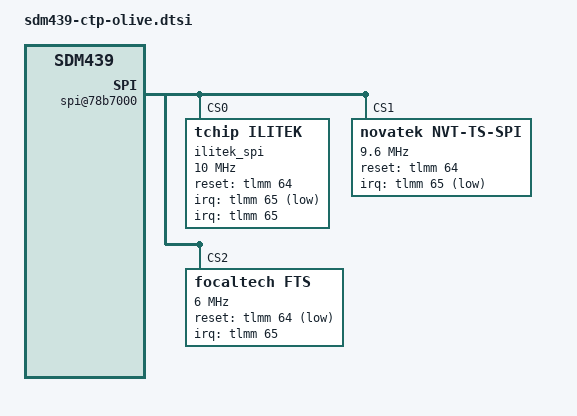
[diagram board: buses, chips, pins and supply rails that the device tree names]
/* Copyright (c) 2018, The Linux Foundation. All rights reserved.
 * Copyright (C) 2021 XiaoMi, Inc.
 *
 * it under the terms of the GNU General Public License version 2 and
 * only version 2 as published by the Free Software Foundation.
 *
 * This program is distributed in the hope that it will be useful,
 * but WITHOUT ANY WARRANTY; without even the implied warranty of
 * MERCHANTABILITY or FITNESS FOR A PARTICULAR PURPOSE.  See the
 * GNU General Public License for more details.
 */

/*
 * As a general rule, only version-specific property overrides should be placed
 * inside this file. However, device definitions should be placed inside the
 * yep_product_ql1001_flatform.dtsi file.
 */

&tlmm {
		ts_int_default: ts_int_default {
			mux {
				pins = "gpio65";
				function = "gpio";
			};
			config {
				pins = "gpio65";
				drive-strength = <8>;
				/*bias-pull-up;*/
				input-enable;
				bias-disable;
			};
		};

		ts_int_output_high: ts_int_output_high {
			mux {
				pins = "gpio65";
				function = "gpio";
			};
			config {
				pins = "gpio65";
				drive-strength = <8>;
				output-high;
				bias-pull-up;
			};
		};

		ts_int_output_low: ts_int_output_low {
			mux {
				pins = "gpio65";
				function = "gpio";
			};
			config {
				pins = "gpio65";
				drive-strength = <8>;
				bias-pull-down;
				output-low;
			};
		};

		ts_int_input: ts_int_input {
			mux {
				pins = "gpio65";
				function = "gpio";
			};
			config {
				pins = "gpio65";
				drive-strength = <8>;
				input-enable;
				bias-disable;
			};
		};

		pmx_ts_reset_release {
			ts_as_reset: ts_as_reset {
				mux {
					pins = "gpio64";
					function = "gpio";
				};

				config {
					pins = "gpio64";
					drive-strength = <8>;
					input-enable;
					bias-disable;
				};
			};
		};

		pmx_ts_reset_suspend {
			ts_reset_suspend: ts_reset_suspend {
				mux {
					pins = "gpio64";
					function = "gpio";
				};

				config {
					pins = "gpio64";
					drive-strength = <8>;
					bias-pull-down;
					output-low;
				};
			};
		};

		pmx_ts_reset_active {
			ts_reset_active: ts_reset_active {
				mux {
					pins = "gpio64";
					function = "gpio";
				};

				config {
					pins = "gpio64";
					drive-strength = <8>;
					bias-pull-up;
					output-high;
				};
			};
		};

		pmx_ts_rst_active {
				ts_rst_active: ts_rst_active {
						mux {
								pins = "gpio64";
								function = "gpio";
						};

						config {
								pins = "gpio64";
								drive-strength = <16>;
								bias-pull-up;
						};
				};
		};

		pmx_ts_rst_suspend {
			ts_rst_suspend: ts_rst_suspend {
						mux {
								pins = "gpio64";
								function = "gpio";
						};

						config {
								pins = "gpio64";
								drive-strength = <2>;
								bias-pull-down;
						};
				};
		};
};


&soc {
	spi@78b7000 {
		status = "okay";
		ilitek_spi@00 {
		    compatible = "tchip,ilitek";
			reg = <0>;
			chip-name = "ILITEK_TDDI";
			status = "ok";

		    poll_mode = <0>;
			spi-max-frequency = <10000000>;
			touch,reset-gpio = <&tlmm 64 0x00>;
			touch,irq-gpio = <&tlmm 65 0x2001>;
			interrupt-parent = <&tlmm>;
			interrupts = <65 0x0>;

			touchpanel,max-num-support = <10>;
			touchpanel,tx-rx-num = <18 32>;
			touchpanel,panel-coords = <720 1520>;
			touchpanel,display-coords = <720 1520>;

			pinctrl-names = "active", "suspend";
			pinctrl-0 = <&ts_int_active &ts_reset_active>;
			pinctrl-1 = <&ts_int_suspend &ts_reset_suspend>;

			incell_screen;
			edge_limit_support;
			black_gesture_support;
			charger_pump_support;
			esd_handle_support;
			//spurious_fingerprint_support;
			//lcd_trigger_fp_check;
			black_gesture_test_support;
			noflash_support;
			smart_gesture_support;

			spi-cpol; //CPOL bit set for SPI polarity
			spi-cpha; //CPHA bit set for SPI Phase
			spi-cs-high; //CS Active High

			/*
			*Virtual Key Config:
			*1:touchpanel,button-type: <virtualkey_type  supportted_button-map>
			*virtualkey_type:
			*Type 1: using board_properties
			*Type 2: using same IC (button zone&& touch zone are seprate)
			*Type 3: using diffrent IC (button zone&& touch zone are seprate)
			*Type 4: No need of virtual key process
			*supportted_button-map:select|menu|home|back
			*
			*2:touchpanel,button-map
			*type (X1,Y1)(X2,Y2)(X3,Y3)(Width_X,Hight_Y)--Only when button-type is 0
			*/

			touchpanel,button-type = <4>;
		};
		novatek@1 {
		compatible = "novatek,NVT-ts-spi";
		reg = <1>; //Same as CS ID
		status = "ok";

		spi-max-frequency = <9600000>;	//4800000,9600000,15000000,19200000
		novatek,reset-gpio = <&tlmm 64 0x00>;
		novatek,irq-gpio = <&tlmm 65 0x2001>;

		/* 525 */
		//novatek,swrst-n8-addr = <0x01F01A>;

		/* 672A, 525B, 675 */
		novatek,swrst-n8-addr = <0x03F0FE>;
		novatek,spi-rd-fast-addr = <0x03F310>;

		/* MP */
		novatek,mp-support-dt;

		/* for Xiaomi C3I 525B BOE 6.217" */
		novatek-mp-criteria-591C@0 {
			#address-cells = <1>;
			#size-cells = <0>;
			compatible = "novatek-mp-criteria-591C";

			/* MP Config */
			ic_x_cfg_size = <18>;
			ic_y_cfg_size = <32>;
			ic_key_cfg_size = <4>;
			x_channel = <18>;
			y_channel = <32>;
			ain_x = <0 1 2 3 4 5 6 7 8 9 10 11 12 13 14 15 16 17>;
			ain_y = <0 1 2 3 4 5 6 7 8 9 10 11 12 13 14 15 16 17
				18 19 20 21 22 23 24 25 26 27 28 29 30 31>;
			ain_key = <0 1 2 0xFF>;
			/* MP Criteria */
			//PS_Config_Lmt_Short_Rawdata_P = <
			    ps_config_lmt_short_rawdata_p = <
				14008 14008 14008 14008 14008 14008 14008 14008 14008 14008 14008 14008 14008 14008 14008 14008 14008 14008
				14008 14008 14008 14008 14008 14008 14008 14008 14008 14008 14008 14008 14008 14008 14008 14008 14008 14008
				14008 14008 14008 14008 14008 14008 14008 14008 14008 14008 14008 14008 14008 14008 14008 14008 14008 14008
				14008 14008 14008 14008 14008 14008 14008 14008 14008 14008 14008 14008 14008 14008 14008 14008 14008 14008
				14008 14008 14008 14008 14008 14008 14008 14008 14008 14008 14008 14008 14008 14008 14008 14008 14008 14008
				14008 14008 14008 14008 14008 14008 14008 14008 14008 14008 14008 14008 14008 14008 14008 14008 14008 14008
				14008 14008 14008 14008 14008 14008 14008 14008 14008 14008 14008 14008 14008 14008 14008 14008 14008 14008
				14008 14008 14008 14008 14008 14008 14008 14008 14008 14008 14008 14008 14008 14008 14008 14008 14008 14008
				14008 14008 14008 14008 14008 14008 14008 14008 14008 14008 14008 14008 14008 14008 14008 14008 14008 14008
				14008 14008 14008 14008 14008 14008 14008 14008 14008 14008 14008 14008 14008 14008 14008 14008 14008 14008
				14008 14008 14008 14008 14008 14008 14008 14008 14008 14008 14008 14008 14008 14008 14008 14008 14008 14008
				14008 14008 14008 14008 14008 14008 14008 14008 14008 14008 14008 14008 14008 14008 14008 14008 14008 14008
				14008 14008 14008 14008 14008 14008 14008 14008 14008 14008 14008 14008 14008 14008 14008 14008 14008 14008
				14008 14008 14008 14008 14008 14008 14008 14008 14008 14008 14008 14008 14008 14008 14008 14008 14008 14008
				14008 14008 14008 14008 14008 14008 14008 14008 14008 14008 14008 14008 14008 14008 14008 14008 14008 14008
				14008 14008 14008 14008 14008 14008 14008 14008 14008 14008 14008 14008 14008 14008 14008 14008 14008 14008
				14008 14008 14008 14008 14008 14008 14008 14008 14008 14008 14008 14008 14008 14008 14008 14008 14008 14008
				14008 14008 14008 14008 14008 14008 14008 14008 14008 14008 14008 14008 14008 14008 14008 14008 14008 14008
				14008 14008 14008 14008 14008 14008 14008 14008 14008 14008 14008 14008 14008 14008 14008 14008 14008 14008
				14008 14008 14008 14008 14008 14008 14008 14008 14008 14008 14008 14008 14008 14008 14008 14008 14008 14008
				14008 14008 14008 14008 14008 14008 14008 14008 14008 14008 14008 14008 14008 14008 14008 14008 14008 14008
				14008 14008 14008 14008 14008 14008 14008 14008 14008 14008 14008 14008 14008 14008 14008 14008 14008 14008
				14008 14008 14008 14008 14008 14008 14008 14008 14008 14008 14008 14008 14008 14008 14008 14008 14008 14008
				14008 14008 14008 14008 14008 14008 14008 14008 14008 14008 14008 14008 14008 14008 14008 14008 14008 14008
				14008 14008 14008 14008 14008 14008 14008 14008 14008 14008 14008 14008 14008 14008 14008 14008 14008 14008
				14008 14008 14008 14008 14008 14008 14008 14008 14008 14008 14008 14008 14008 14008 14008 14008 14008 14008
				14008 14008 14008 14008 14008 14008 14008 14008 14008 14008 14008 14008 14008 14008 14008 14008 14008 14008
				14008 14008 14008 14008 14008 14008 14008 14008 14008 14008 14008 14008 14008 14008 14008 14008 14008 14008
				14008 14008 14008 14008 14008 14008 14008 14008 14008 14008 14008 14008 14008 14008 14008 14008 14008 14008
				14008 14008 14008 14008 14008 14008 14008 14008 14008 14008 14008 14008 14008 14008 14008 14008 14008 14008
				14008 14008 14008 14008 14008 14008 14008 14008 14008 14008 14008 14008 14008 14008 14008 14008 14008 14008
				14008 14008 14008 14008 14008 14008 14008 14008 14008 14008 14008 14008 14008 14008 14008 14008 14008 14008
				14008 14008 14008>;

			//PS_Config_Lmt_Short_Rawdata_N = <
			    ps_config_lmt_short_rawdata_n = <
				11376 11376 11376 11376 11376 11376 11376 11376 11376 11376 11376 11376 11376 11376 11376 11376 11376 11376
				11376 11376 11376 11376 11376 11376 11376 11376 11376 11376 11376 11376 11376 11376 11376 11376 11376 11376
				11376 11376 11376 11376 11376 11376 11376 11376 11376 11376 11376 11376 11376 11376 11376 11376 11376 11376
				11376 11376 11376 11376 11376 11376 11376 11376 11376 11376 11376 11376 11376 11376 11376 11376 11376 11376
				11376 11376 11376 11376 11376 11376 11376 11376 11376 11376 11376 11376 11376 11376 11376 11376 11376 11376
				11376 11376 11376 11376 11376 11376 11376 11376 11376 11376 11376 11376 11376 11376 11376 11376 11376 11376
				11376 11376 11376 11376 11376 11376 11376 11376 11376 11376 11376 11376 11376 11376 11376 11376 11376 11376
				11376 11376 11376 11376 11376 11376 11376 11376 11376 11376 11376 11376 11376 11376 11376 11376 11376 11376
				11376 11376 11376 11376 11376 11376 11376 11376 11376 11376 11376 11376 11376 11376 11376 11376 11376 11376
				11376 11376 11376 11376 11376 11376 11376 11376 11376 11376 11376 11376 11376 11376 11376 11376 11376 11376
				11376 11376 11376 11376 11376 11376 11376 11376 11376 11376 11376 11376 11376 11376 11376 11376 11376 11376
				11376 11376 11376 11376 11376 11376 11376 11376 11376 11376 11376 11376 11376 11376 11376 11376 11376 11376
				11376 11376 11376 11376 11376 11376 11376 11376 11376 11376 11376 11376 11376 11376 11376 11376 11376 11376
				11376 11376 11376 11376 11376 11376 11376 11376 11376 11376 11376 11376 11376 11376 11376 11376 11376 11376
				11376 11376 11376 11376 11376 11376 11376 11376 11376 11376 11376 11376 11376 11376 11376 11376 11376 11376
				11376 11376 11376 11376 11376 11376 11376 11376 11376 11376 11376 11376 11376 11376 11376 11376 11376 11376
				11376 11376 11376 11376 11376 11376 11376 11376 11376 11376 11376 11376 11376 11376 11376 11376 11376 11376
				11376 11376 11376 11376 11376 11376 11376 11376 11376 11376 11376 11376 11376 11376 11376 11376 11376 11376
				11376 11376 11376 11376 11376 11376 11376 11376 11376 11376 11376 11376 11376 11376 11376 11376 11376 11376
				11376 11376 11376 11376 11376 11376 11376 11376 11376 11376 11376 11376 11376 11376 11376 11376 11376 11376
				11376 11376 11376 11376 11376 11376 11376 11376 11376 11376 11376 11376 11376 11376 11376 11376 11376 11376
				11376 11376 11376 11376 11376 11376 11376 11376 11376 11376 11376 11376 11376 11376 11376 11376 11376 11376
				11376 11376 11376 11376 11376 11376 11376 11376 11376 11376 11376 11376 11376 11376 11376 11376 11376 11376
				11376 11376 11376 11376 11376 11376 11376 11376 11376 11376 11376 11376 11376 11376 11376 11376 11376 11376
				11376 11376 11376 11376 11376 11376 11376 11376 11376 11376 11376 11376 11376 11376 11376 11376 11376 11376
				11376 11376 11376 11376 11376 11376 11376 11376 11376 11376 11376 11376 11376 11376 11376 11376 11376 11376
				11376 11376 11376 11376 11376 11376 11376 11376 11376 11376 11376 11376 11376 11376 11376 11376 11376 11376
				11376 11376 11376 11376 11376 11376 11376 11376 11376 11376 11376 11376 11376 11376 11376 11376 11376 11376
				11376 11376 11376 11376 11376 11376 11376 11376 11376 11376 11376 11376 11376 11376 11376 11376 11376 11376
				11376 11376 11376 11376 11376 11376 11376 11376 11376 11376 11376 11376 11376 11376 11376 11376 11376 11376
				11376 11376 11376 11376 11376 11376 11376 11376 11376 11376 11376 11376 11376 11376 11376 11376 11376 11376
				11376 11376 11376 11376 11376 11376 11376 11376 11376 11376 11376 11376 11376 11376 11376 11376 11376 11376
				10000 10000 10000>;

			//PS_Config_Lmt_Open_Rawdata_P = <
			    ps_config_lmt_open_rawdata_p = <
				65535 2420 2548 2510 2524 2457 2476 2326 65535 65535 2352 2500 2506 2542 2507 2476 2371 65535
				2262 2298 2356 2332 2357 2328 2349 2319 2251 2276 2354 2373 2373 2382 2339 2303 2259 2205
				2303 2314 2375 2354 2381 2352 2367 2339 2346 2382 2381 2398 2399 2410 2364 2324 2280 2248
				2321 2333 2396 2375 2402 2374 2389 2357 2364 2410 2410 2433 2434 2444 2398 2360 2315 2286
				2322 2332 2391 2373 2394 2367 2381 2352 2360 2380 2380 2401 2399 2413 2375 2340 2298 2272
				2340 2354 2409 2394 2413 2388 2394 2367 2375 2408 2406 2427 2431 2447 2409 2373 2333 2305
				2370 2387 2454 2437 2459 2433 2440 2415 2424 2441 2438 2457 2459 2478 2438 2405 2353 2324
				2388 2408 2475 2464 2476 2454 2459 2437 2445 2462 2461 2479 2483 2500 2471 2437 2385 2356
				2374 2388 2454 2438 2454 2429 2437 2415 2420 2431 2430 2451 2451 2471 2441 2416 2367 2340
				2405 2420 2482 2471 2482 2458 2464 2441 2447 2451 2451 2472 2478 2494 2471 2447 2398 2371
				2434 2450 2517 2503 2521 2494 2500 2476 2480 2497 2497 2521 2524 2543 2518 2494 2444 2416
				2450 2465 2528 2518 2534 2508 2513 2490 2493 2518 2520 2542 2545 2564 2542 2518 2471 2443
				2441 2454 2514 2497 2517 2492 2496 2469 2476 2478 2480 2506 2507 2528 2508 2492 2450 2424
				2464 2475 2534 2520 2536 2510 2517 2489 2493 2503 2506 2531 2534 2555 2543 2527 2486 2459
				2517 2529 2590 2577 2595 2569 2576 2548 2552 2532 2536 2562 2563 2584 2574 2559 2515 2487
				2521 2531 2590 2580 2594 2567 2574 2548 2549 2552 2556 2581 2585 2605 2599 2585 2542 2514
				2515 2527 2573 2577 2594 2569 2577 2550 2549 2521 2524 2546 2550 2570 2571 2573 2538 2515
				2524 2534 2578 2578 2597 2573 2580 2553 2553 2548 2553 2576 2580 2598 2599 2608 2574 2552
				2576 2591 2634 2636 2657 2633 2640 2612 2613 2577 2580 2604 2608 2626 2626 2637 2606 2581
				2580 2591 2632 2629 2653 2627 2636 2608 2609 2598 2602 2625 2629 2647 2648 2661 2633 2609
				2577 2587 2619 2618 2640 2613 2632 2605 2609 2560 2562 2583 2576 2598 2598 2615 2591 2571
				2573 2581 2623 2615 2633 2606 2625 2597 2601 2591 2592 2616 2609 2629 2634 2657 2630 2609
				2639 2646 2689 2682 2702 2675 2692 2667 2669 2625 2627 2651 2643 2664 2668 2692 2664 2644
				2637 2646 2688 2678 2700 2672 2689 2662 2667 2647 2650 2674 2667 2688 2690 2720 2693 2674
				2626 2633 2669 2657 2682 2650 2665 2639 2643 2594 2595 2618 2611 2639 2636 2665 2644 2629
				2616 2622 2658 2644 2669 2637 2654 2625 2632 2612 2611 2637 2630 2660 2657 2685 2667 2654
				2685 2689 2725 2718 2746 2713 2724 2696 2702 2653 2650 2679 2674 2706 2697 2725 2704 2690
				2668 2671 2704 2696 2724 2696 2707 2674 2679 2671 2664 2702 2695 2723 2716 2744 2725 2710
				2644 2651 2679 2669 2692 2667 2676 2643 2650 2604 2592 2633 2623 2655 2646 2676 2658 2648
				2277 2658 2688 2674 2696 2671 2683 2650 2657 2640 2627 2669 2658 2692 2682 2716 2697 2293
				2328 2716 2744 2731 2753 2730 2742 2709 2717 2669 2655 2697 2685 2720 2710 2746 2727 2321
				2308 2620 2738 2724 2749 2727 2739 2707 2721 2713 2690 2734 2720 2756 2746 2784 2675 2346
				4096 4096 4096>;

			//PS_Config_Lmt_Open_Rawdata_N = <
			    ps_config_lmt_open_rawdata_n = <
				(-65535) 1037 1092 1075 1081 1053 1061 997 (-65535) (-65535) 1008 1071 1074 1089 1074 1061 1016 (-65535)
				969 985 1009 999 1010 997 1006 994 964 975 1009 1017 1017 1021 1002 987 968 945
				987 991 1018 1009 1020 1008 1014 1002 1005 1021 1020 1027 1028 1033 1013 996 977 963
				994 1000 1027 1018 1029 1017 1024 1010 1013 1033 1033 1042 1043 1047 1027 1011 992 979
				995 999 1024 1017 1026 1014 1020 1008 1011 1020 1020 1029 1028 1034 1018 1003 985 973
				1003 1009 1032 1026 1034 1023 1026 1014 1018 1032 1031 1040 1042 1048 1032 1017 1000 988
				1015 1023 1051 1044 1054 1042 1045 1035 1039 1046 1045 1053 1054 1062 1045 1030 1008 996
				1023 1032 1060 1056 1061 1051 1054 1044 1048 1055 1054 1062 1064 1071 1059 1044 1022 1009
				1017 1023 1051 1045 1051 1041 1044 1035 1037 1042 1041 1050 1050 1059 1046 1035 1014 1003
				1030 1037 1063 1059 1063 1053 1056 1046 1048 1050 1050 1059 1062 1069 1059 1048 1027 1016
				1043 1050 1078 1072 1080 1069 1071 1061 1063 1070 1070 1080 1081 1090 1079 1069 1047 1035
				1050 1056 1083 1079 1086 1075 1077 1067 1068 1079 1080 1089 1090 1099 1089 1079 1059 1047
				1046 1051 1077 1070 1078 1068 1069 1058 1061 1062 1063 1074 1074 1083 1075 1068 1050 1039
				1056 1060 1086 1080 1087 1075 1078 1066 1068 1072 1074 1084 1086 1095 1090 1083 1065 1054
				1078 1084 1110 1104 1112 1101 1104 1092 1093 1085 1087 1098 1098 1107 1103 1096 1078 1066
				1080 1084 1110 1105 1111 1100 1103 1092 1092 1093 1095 1106 1108 1116 1114 1108 1089 1077
				1078 1083 1102 1104 1111 1101 1104 1093 1092 1080 1081 1091 1093 1101 1102 1102 1087 1078
				1081 1086 1105 1105 1113 1102 1105 1094 1094 1092 1094 1104 1105 1113 1114 1117 1103 1093
				1104 1110 1129 1129 1138 1128 1131 1119 1120 1104 1105 1116 1117 1125 1125 1130 1117 1106
				1105 1110 1128 1126 1137 1126 1129 1117 1118 1113 1115 1125 1126 1134 1135 1140 1128 1118
				1104 1108 1122 1122 1131 1120 1128 1116 1118 1097 1098 1107 1104 1113 1113 1120 1110 1102
				1102 1106 1124 1120 1128 1117 1125 1113 1114 1110 1111 1121 1118 1126 1129 1138 1127 1118
				1131 1134 1152 1149 1158 1146 1153 1143 1144 1125 1126 1136 1132 1141 1143 1153 1141 1133
				1130 1134 1152 1147 1157 1145 1152 1141 1143 1134 1135 1146 1143 1152 1153 1165 1154 1146
				1125 1128 1144 1138 1149 1135 1142 1131 1132 1111 1112 1122 1119 1131 1129 1142 1133 1126
				1121 1123 1139 1133 1144 1130 1137 1125 1128 1119 1119 1130 1127 1140 1138 1150 1143 1137
				1150 1152 1168 1165 1177 1162 1167 1155 1158 1137 1135 1148 1146 1159 1156 1168 1159 1153
				1143 1144 1159 1155 1167 1155 1160 1146 1148 1144 1141 1158 1155 1167 1164 1176 1168 1161
				1133 1136 1148 1144 1153 1143 1147 1132 1135 1116 1111 1128 1124 1138 1134 1147 1139 1135
				976 1139 1152 1146 1155 1144 1150 1135 1138 1131 1126 1144 1139 1153 1149 1164 1156 982
				997 1164 1176 1170 1180 1170 1175 1161 1164 1144 1138 1156 1150 1165 1161 1177 1168 994
				989 1123 1173 1167 1178 1168 1174 1160 1166 1162 1153 1171 1165 1181 1177 1193 1146 1005
				50 50 50>;

			//PS_Config_Lmt_FW_Rawdata_P = <
			   ps_config_lmt_fw_rawdata_p = <
				65535 837 841 840 840 833 838 840 65535 65535 833 841 828 837 849 851 851 65535
				838 835 847 842 834 845 828 831 842 833 833 838 847 833 834 847 840 835
				837 848 851 851 848 848 838 840 824 844 844 847 849 838 830 845 845 833
				844 840 837 841 841 848 841 845 842 851 845 842 834 834 842 838 838 837
				842 828 831 831 834 841 849 848 847 844 842 838 841 831 841 849 845 844
				842 833 840 837 837 840 842 842 845 852 845 842 840 837 840 844 842 842
				834 841 842 845 842 847 838 844 844 842 842 844 833 842 833 838 844 841
				835 828 828 847 842 851 849 847 851 828 826 824 830 841 828 851 834 841
				833 847 838 828 838 842 840 845 840 845 831 841 833 833 848 847 847 842
				827 831 834 830 841 837 840 834 831 835 837 837 834 845 841 837 837 844
				826 834 827 833 841 855 851 855 862 827 835 845 835 847 844 840 842 847
				845 840 838 841 835 838 842 841 845 830 828 851 834 854 851 840 847 835
				841 847 847 828 833 828 837 837 835 845 855 858 862 847 858 840 838 844
				830 831 827 838 838 844 849 851 848 841 837 842 835 841 842 845 856 845
				842 845 842 840 851 847 848 842 837 847 827 849 840 849 841 834 840 833
				840 830 837 827 831 833 830 827 841 849 840 835 838 831 831 835 831 840
				838 844 835 842 848 841 848 842 845 848 838 840 840 835 844 830 842 838
				854 833 830 848 835 854 841 844 847 834 826 833 827 851 828 854 840 827
				841 837 837 838 835 847 842 847 845 837 841 835 835 834 841 831 834 847
				838 845 838 828 827 838 838 834 838 837 837 841 834 844 835 848 831 834
				842 840 835 841 840 845 848 842 842 840 841 828 834 827 828 826 826 849
				841 841 840 838 838 830 835 833 841 834 838 838 840 848 845 835 849 833
				844 848 834 841 840 840 845 840 842 847 848 838 848 831 844 835 845 841
				837 840 834 842 834 834 838 838 835 838 840 838 840 835 837 834 833 851
				847 838 837 842 831 841 842 842 844 840 847 841 844 838 847 847 845 824
				837 838 842 845 835 840 841 835 838 841 837 827 831 835 831 827 833 842
				852 835 819 835 830 838 833 838 845 834 844 847 848 841 845 847 848 837
				844 841 844 840 845 851 841 841 835 844 826 830 834 851 833 835 837 842
				840 838 830 837 830 837 838 841 835 835 830 830 833 835 831 830 841 841
				845 842 840 841 844 849 845 855 842 848 842 842 840 844 837 834 835 840
				844 842 828 838 838 838 841 847 833 834 840 835 835 840 847 840 837 840
				841 840 841 844 842 845 834 838 844 841 841 838 840 842 845 847 841 833
				1920 1920 1920>;

			//PS_Config_Lmt_FW_Rawdata_N = <
			    ps_config_lmt_fw_rawdata_n = <
				(-65535) 358 360 360 360 357 359 360 (-65535) (-65535) 357 360 355 358 364 364 364 (-65535)
				359 358 363 361 357 362 355 356 361 357 357 359 363 357 357 363 360 358
				358 363 364 364 363 363 359 360 353 361 361 363 364 359 355 362 362 357
				361 360 358 360 360 363 360 362 361 364 362 361 357 357 361 359 359 358
				361 355 356 356 357 360 364 363 363 361 361 359 360 356 360 364 362 361
				361 357 360 358 358 360 361 361 362 365 362 361 360 358 360 361 361 361
				357 360 361 362 361 363 359 361 361 361 361 361 357 361 357 359 361 360
				358 355 355 363 361 364 364 363 364 355 354 353 355 360 355 364 357 360
				357 363 359 355 359 361 360 362 360 362 356 360 357 357 363 363 363 361
				354 356 357 355 360 358 360 357 356 358 358 358 357 362 360 358 358 361
				354 357 354 357 360 366 364 366 369 354 358 362 358 363 361 360 361 363
				362 360 359 360 358 359 361 360 362 355 355 364 357 366 364 360 363 358
				360 363 363 355 357 355 358 358 358 362 366 367 369 363 367 360 359 361
				355 356 354 359 359 361 364 364 363 360 358 361 358 360 361 362 367 362
				361 362 361 360 364 363 363 361 358 363 354 364 360 364 360 357 360 357
				360 355 358 354 356 357 355 354 360 364 360 358 359 356 356 358 356 360
				359 361 358 361 363 360 363 361 362 363 359 360 360 358 361 355 361 359
				366 357 355 363 358 366 360 361 363 357 354 357 354 364 355 366 360 354
				360 358 358 359 358 363 361 363 362 358 360 358 358 357 360 356 357 363
				359 362 359 355 354 359 359 357 359 358 358 360 357 361 358 363 356 357
				361 360 358 360 360 362 363 361 361 360 360 355 357 354 355 354 354 364
				360 360 360 359 359 355 358 357 360 357 359 359 360 363 362 358 364 357
				361 363 357 360 360 360 362 360 361 363 363 359 363 356 361 358 362 360
				358 360 357 361 357 357 359 359 358 359 360 359 360 358 358 357 357 364
				363 359 358 361 356 360 361 361 361 360 363 360 361 359 363 363 362 353
				358 359 361 362 358 360 360 358 359 360 358 354 356 358 356 354 357 361
				365 358 351 358 355 359 357 359 362 357 361 363 363 360 362 363 363 358
				361 360 361 360 362 364 360 360 358 361 354 355 357 364 357 358 358 361
				360 359 355 358 355 358 359 360 358 358 355 355 357 358 356 355 360 360
				362 361 360 360 361 364 362 366 361 363 361 361 360 361 358 357 358 360
				361 361 355 359 359 359 360 363 357 357 360 358 358 360 363 360 358 360
				360 360 360 361 361 362 357 359 361 360 360 359 360 361 362 363 360 357
				240 240 240>;

			//PS_Config_Lmt_FW_CC_P = <
			   ps_config_lmt_fw_cc_p = <
				65535 78 78 78 78 78 80 80 65535 65535 80 78 78 78 78 78 78 65535
				78 77 77 78 78 78 78 78 78 78 78 78 78 78 77 77 77 77
				78 77 77 77 77 77 78 78 78 77 77 77 77 77 77 77 77 77
				78 78 78 78 78 78 78 78 78 80 80 78 80 78 78 78 78 78
				77 77 77 77 77 77 78 78 78 78 78 78 78 78 77 77 77 77
				78 78 78 78 78 78 78 78 78 78 78 78 78 78 78 78 78 78
				78 77 78 78 78 78 78 78 78 78 78 77 78 77 77 77 77 77
				78 78 78 78 78 78 80 80 80 80 80 78 78 78 78 78 78 78
				77 77 77 77 77 78 78 78 78 77 77 77 77 77 77 77 77 77
				78 78 78 78 78 80 78 80 80 78 78 78 78 78 78 78 78 78
				78 78 78 78 78 78 78 78 78 78 78 77 78 77 77 77 77 77
				78 78 78 78 78 78 78 78 80 80 80 78 78 78 78 78 78 78
				78 77 77 78 78 78 78 78 78 77 77 77 77 77 77 77 77 77
				78 78 78 78 78 78 78 78 78 78 78 78 78 78 78 78 78 78
				78 78 77 78 78 78 78 78 78 77 78 77 77 77 77 77 77 77
				78 78 78 78 78 78 78 78 80 78 78 78 78 78 78 78 78 78
				77 77 77 77 77 77 77 77 77 75 75 75 75 75 75 75 75 75
				75 75 75 75 75 75 75 75 75 75 77 75 77 75 75 75 75 77
				77 77 77 77 77 77 77 77 77 75 75 75 75 75 75 75 75 75
				77 75 75 77 77 77 77 77 77 77 77 77 77 75 77 75 77 77
				77 77 77 77 77 77 77 77 77 75 75 75 75 75 75 75 75 75
				77 75 75 77 77 77 77 77 77 77 77 77 77 75 77 77 75 77
				78 77 77 77 77 77 77 77 78 77 77 77 77 75 77 77 77 77
				77 77 77 77 77 77 77 77 77 77 77 77 77 77 77 77 77 78
				77 77 77 77 77 77 77 77 77 77 77 75 77 75 75 75 77 77
				77 77 77 77 77 77 77 77 77 77 77 77 77 77 77 77 77 77
				78 78 78 78 78 78 78 78 78 77 77 77 77 75 77 77 77 77
				77 77 77 77 77 77 77 77 78 78 77 77 77 77 77 77 78 78
				78 77 77 77 77 77 77 77 78 77 77 77 77 75 77 77 77 77
				77 77 77 77 77 77 77 77 78 78 77 77 77 77 77 77 77 77
				77 77 77 77 77 78 78 78 78 78 77 77 77 77 77 77 77 77
				78 78 78 78 78 78 78 78 80 80 78 78 78 78 78 78 78 78
				314 314 314>;

			//PS_Config_Lmt_FW_CC_N = <
			   ps_config_lmt_fw_cc_n = <
				(-65535) 35 35 35 35 35 35 35 (-65535) (-65535) 35 35 35 35 35 35 35 (-65535)
				35 34 34 35 35 35 35 35 35 35 35 35 35 35 34 34 34 34
				35 34 34 34 34 34 35 35 35 34 34 34 34 34 34 34 34 34
				35 35 35 35 35 35 35 35 35 35 35 35 35 35 35 35 35 35
				34 34 34 34 34 34 35 35 35 35 35 35 35 35 34 34 34 34
				35 35 35 35 35 35 35 35 35 35 35 35 35 35 35 35 35 35
				35 34 35 35 35 35 35 35 35 35 35 34 35 34 34 34 34 34
				35 35 35 35 35 35 35 35 35 35 35 35 35 35 35 35 35 35
				34 34 34 34 34 35 35 35 35 34 34 34 34 34 34 34 34 34
				35 35 35 35 35 35 35 35 35 35 35 35 35 35 35 35 35 35
				35 35 35 35 35 35 35 35 35 35 35 34 35 34 34 34 34 34
				35 35 35 35 35 35 35 35 35 35 35 35 35 35 35 35 35 35
				35 34 34 35 35 35 35 35 35 34 34 34 34 34 34 34 34 34
				35 35 35 35 35 35 35 35 35 35 35 35 35 35 35 35 35 35
				35 35 34 35 35 35 35 35 35 34 35 34 34 34 34 34 34 34
				35 35 35 35 35 35 35 35 35 35 35 35 35 35 35 35 35 35
				34 34 34 34 34 34 34 34 34 34 34 34 34 34 34 34 34 34
				34 34 34 34 34 34 34 34 34 34 34 34 34 34 34 34 34 34
				34 34 34 34 34 34 34 34 34 34 34 34 34 34 34 34 34 34
				34 34 34 34 34 34 34 34 34 34 34 34 34 34 34 34 34 34
				34 34 34 34 34 34 34 34 34 34 34 34 34 34 34 34 34 34
				34 34 34 34 34 34 34 34 34 34 34 34 34 34 34 34 34 34
				35 34 34 34 34 34 34 34 35 34 34 34 34 34 34 34 34 34
				34 34 34 34 34 34 34 34 34 34 34 34 34 34 34 34 34 35
				34 34 34 34 34 34 34 34 34 34 34 34 34 34 34 34 34 34
				34 34 34 34 34 34 34 34 34 34 34 34 34 34 34 34 34 34
				35 35 35 35 35 35 35 35 35 34 34 34 34 34 34 34 34 34
				34 34 34 34 34 34 34 34 35 35 34 34 34 34 34 34 35 35
				35 34 34 34 34 34 34 34 35 34 34 34 34 34 34 34 34 34
				34 34 34 34 34 34 34 34 35 35 34 34 34 34 34 34 34 34
				34 34 34 34 34 35 35 35 35 35 34 34 34 34 34 34 34 34
				35 35 35 35 35 35 35 35 35 35 35 35 35 35 35 35 35 35
				30 30 30>;

			//PS_Config_Lmt_FW_Diff_P = <
			   ps_config_lmt_fw_diff_p = <
				65535 50 50 50 50 50 50 50 65535 65535 50 50 50 50 50 50 50 65535
				50 50 50 50 50 50 50 50 50 50 50 50 50 50 50 50 50 50
				50 50 50 50 50 50 50 50 50 50 50 50 50 50 50 50 50 50
				50 50 50 50 50 50 50 50 50 50 50 50 50 50 50 50 50 50
				50 50 50 50 50 50 50 50 50 50 50 50 50 50 50 50 50 50
				50 50 50 50 50 50 50 50 50 50 50 50 50 50 50 50 50 50
				50 50 50 50 50 50 50 50 50 50 50 50 50 50 50 50 50 50
				50 50 50 50 50 50 50 50 50 50 50 50 50 50 50 50 50 50
				50 50 50 50 50 50 50 50 50 50 50 50 50 50 50 50 50 50
				50 50 50 50 50 50 50 50 50 50 50 50 50 50 50 50 50 50
				50 50 50 50 50 50 50 50 50 50 50 50 50 50 50 50 50 50
				50 50 50 50 50 50 50 50 50 50 50 50 50 50 50 50 50 50
				50 50 50 50 50 50 50 50 50 50 50 50 50 50 50 50 50 50
				50 50 50 50 50 50 50 50 50 50 50 50 50 50 50 50 50 50
				50 50 50 50 50 50 50 50 50 50 50 50 50 50 50 50 50 50
				50 50 50 50 50 50 50 50 50 50 50 50 50 50 50 50 50 50
				50 50 50 50 50 50 50 50 50 50 50 50 50 50 50 50 50 50
				50 50 50 50 50 50 50 50 50 50 50 50 50 50 50 50 50 50
				50 50 50 50 50 50 50 50 50 50 50 50 50 50 50 50 50 50
				50 50 50 50 50 50 50 50 50 50 50 50 50 50 50 50 50 50
				50 50 50 50 50 50 50 50 50 50 50 50 50 50 50 50 50 50
				50 50 50 50 50 50 50 50 50 50 50 50 50 50 50 50 50 50
				50 50 50 50 50 50 50 50 50 50 50 50 50 50 50 50 50 50
				50 50 50 50 50 50 50 50 50 50 50 50 50 50 50 50 50 50
				50 50 50 50 50 50 50 50 50 50 50 50 50 50 50 50 50 50
				50 50 50 50 50 50 50 50 50 50 50 50 50 50 50 50 50 50
				50 50 50 50 50 50 50 50 50 50 50 50 50 50 50 50 50 50
				50 50 50 50 50 50 50 50 50 50 50 50 50 50 50 50 50 50
				50 50 50 50 50 50 50 50 50 50 50 50 50 50 50 50 50 50
				50 50 50 50 50 50 50 50 50 50 50 50 50 50 50 50 50 50
				50 50 50 50 50 50 50 50 50 50 50 50 50 50 50 50 50 50
				50 50 50 50 50 50 50 50 50 50 50 50 50 50 50 50 50 50
				75 75 75>;

			//PS_Config_Lmt_FW_Diff_N = <
			   ps_config_lmt_fw_diff_n = <
				(-65535) (-50) (-50) (-50) (-50) (-50) (-50) (-50) (-65535) (-65535) (-50) (-50) (-50) (-50) (-50) (-50) (-50) (-65535)
				(-50) (-50) (-50) (-50) (-50) (-50) (-50) (-50) (-50) (-50) (-50) (-50) (-50) (-50) (-50) (-50) (-50) (-50)
				(-50) (-50) (-50) (-50) (-50) (-50) (-50) (-50) (-50) (-50) (-50) (-50) (-50) (-50) (-50) (-50) (-50) (-50)
				(-50) (-50) (-50) (-50) (-50) (-50) (-50) (-50) (-50) (-50) (-50) (-50) (-50) (-50) (-50) (-50) (-50) (-50)
				(-50) (-50) (-50) (-50) (-50) (-50) (-50) (-50) (-50) (-50) (-50) (-50) (-50) (-50) (-50) (-50) (-50) (-50)
				(-50) (-50) (-50) (-50) (-50) (-50) (-50) (-50) (-50) (-50) (-50) (-50) (-50) (-50) (-50) (-50) (-50) (-50)
				(-50) (-50) (-50) (-50) (-50) (-50) (-50) (-50) (-50) (-50) (-50) (-50) (-50) (-50) (-50) (-50) (-50) (-50)
				(-50) (-50) (-50) (-50) (-50) (-50) (-50) (-50) (-50) (-50) (-50) (-50) (-50) (-50) (-50) (-50) (-50) (-50)
				(-50) (-50) (-50) (-50) (-50) (-50) (-50) (-50) (-50) (-50) (-50) (-50) (-50) (-50) (-50) (-50) (-50) (-50)
				(-50) (-50) (-50) (-50) (-50) (-50) (-50) (-50) (-50) (-50) (-50) (-50) (-50) (-50) (-50) (-50) (-50) (-50)
				(-50) (-50) (-50) (-50) (-50) (-50) (-50) (-50) (-50) (-50) (-50) (-50) (-50) (-50) (-50) (-50) (-50) (-50)
				(-50) (-50) (-50) (-50) (-50) (-50) (-50) (-50) (-50) (-50) (-50) (-50) (-50) (-50) (-50) (-50) (-50) (-50)
				(-50) (-50) (-50) (-50) (-50) (-50) (-50) (-50) (-50) (-50) (-50) (-50) (-50) (-50) (-50) (-50) (-50) (-50)
				(-50) (-50) (-50) (-50) (-50) (-50) (-50) (-50) (-50) (-50) (-50) (-50) (-50) (-50) (-50) (-50) (-50) (-50)
				(-50) (-50) (-50) (-50) (-50) (-50) (-50) (-50) (-50) (-50) (-50) (-50) (-50) (-50) (-50) (-50) (-50) (-50)
				(-50) (-50) (-50) (-50) (-50) (-50) (-50) (-50) (-50) (-50) (-50) (-50) (-50) (-50) (-50) (-50) (-50) (-50)
				(-50) (-50) (-50) (-50) (-50) (-50) (-50) (-50) (-50) (-50) (-50) (-50) (-50) (-50) (-50) (-50) (-50) (-50)
				(-50) (-50) (-50) (-50) (-50) (-50) (-50) (-50) (-50) (-50) (-50) (-50) (-50) (-50) (-50) (-50) (-50) (-50)
				(-50) (-50) (-50) (-50) (-50) (-50) (-50) (-50) (-50) (-50) (-50) (-50) (-50) (-50) (-50) (-50) (-50) (-50)
				(-50) (-50) (-50) (-50) (-50) (-50) (-50) (-50) (-50) (-50) (-50) (-50) (-50) (-50) (-50) (-50) (-50) (-50)
				(-50) (-50) (-50) (-50) (-50) (-50) (-50) (-50) (-50) (-50) (-50) (-50) (-50) (-50) (-50) (-50) (-50) (-50)
				(-50) (-50) (-50) (-50) (-50) (-50) (-50) (-50) (-50) (-50) (-50) (-50) (-50) (-50) (-50) (-50) (-50) (-50)
				(-50) (-50) (-50) (-50) (-50) (-50) (-50) (-50) (-50) (-50) (-50) (-50) (-50) (-50) (-50) (-50) (-50) (-50)
				(-50) (-50) (-50) (-50) (-50) (-50) (-50) (-50) (-50) (-50) (-50) (-50) (-50) (-50) (-50) (-50) (-50) (-50)
				(-50) (-50) (-50) (-50) (-50) (-50) (-50) (-50) (-50) (-50) (-50) (-50) (-50) (-50) (-50) (-50) (-50) (-50)
				(-50) (-50) (-50) (-50) (-50) (-50) (-50) (-50) (-50) (-50) (-50) (-50) (-50) (-50) (-50) (-50) (-50) (-50)
				(-50) (-50) (-50) (-50) (-50) (-50) (-50) (-50) (-50) (-50) (-50) (-50) (-50) (-50) (-50) (-50) (-50) (-50)
				(-50) (-50) (-50) (-50) (-50) (-50) (-50) (-50) (-50) (-50) (-50) (-50) (-50) (-50) (-50) (-50) (-50) (-50)
				(-50) (-50) (-50) (-50) (-50) (-50) (-50) (-50) (-50) (-50) (-50) (-50) (-50) (-50) (-50) (-50) (-50) (-50)
				(-50) (-50) (-50) (-50) (-50) (-50) (-50) (-50) (-50) (-50) (-50) (-50) (-50) (-50) (-50) (-50) (-50) (-50)
				(-50) (-50) (-50) (-50) (-50) (-50) (-50) (-50) (-50) (-50) (-50) (-50) (-50) (-50) (-50) (-50) (-50) (-50)
				(-50) (-50) (-50) (-50) (-50) (-50) (-50) (-50) (-50) (-50) (-50) (-50) (-50) (-50) (-50) (-50) (-50) (-50)
				(-75) (-75) (-75)>;

			ps_config_diff_test_frame = <50>;
		};
	};
		focaltech@2 {
			status = "ok";
			compatible = "focaltech,fts";
			reg = <2>;
			spi-max-frequency = <6000000>;
			interrupt-parent = <&tlmm>;
			interrupts = <65 0x2>;
			focaltech,reset-gpio = <&tlmm 64 0x01>;
			focaltech,irq-gpio = <&tlmm 65 0x02>;
			focaltech,max-touch-number = <10>;
			focaltech,display-coords =  <0 0 720 1520>;

			pinctrl-names = "pmx_ts_active","pmx_ts_suspend","pmx_ts_release";
			pinctrl-0 = <&ts_int_active &ts_reset_active>;
			pinctrl-1 = <&ts_int_suspend &ts_reset_suspend>;
			pinctrl-2 = <&ts_release>;
		};
	};
};

